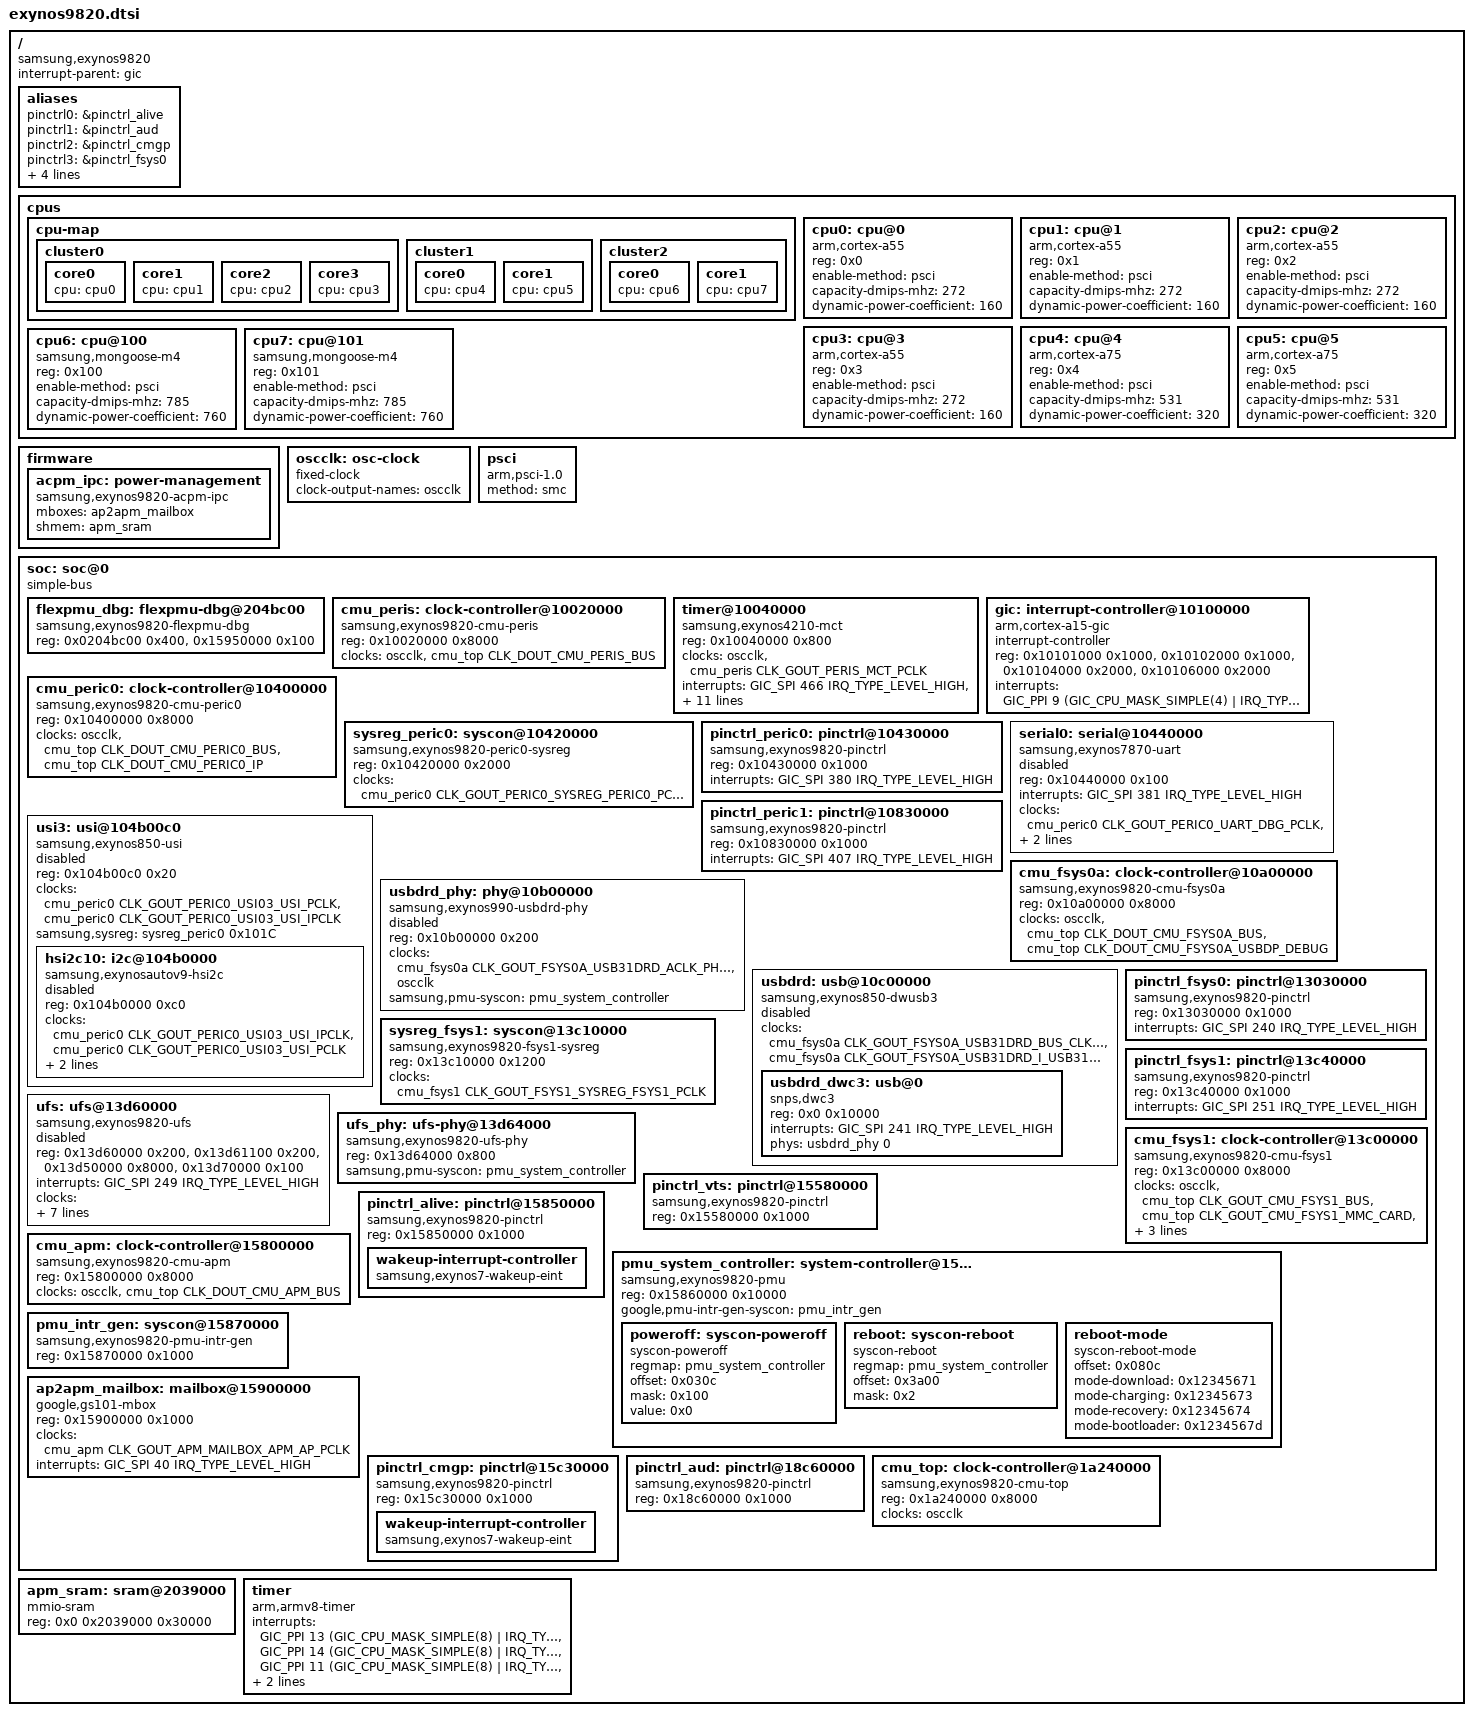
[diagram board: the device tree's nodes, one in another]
// SPDX-License-Identifier: GPL-2.0 OR BSD-3-Clause
/*
 * Samsung Exynos 9820 SoC device tree source
 *
 * Copyright (c) 2025 chiffathefox <chiffathefoxx@gmail.com>
 */

#include <dt-bindings/clock/exynos9820.h>
#include <dt-bindings/interrupt-controller/arm-gic.h>
#include <dt-bindings/interrupt-controller/exynos9820.h>

/ {
	compatible = "samsung,exynos9820";
	#address-cells = <2>;
	#size-cells = <1>;

	interrupt-parent = <&gic>;

	aliases {
		pinctrl0 = &pinctrl_alive;
		pinctrl1 = &pinctrl_aud;
		pinctrl2 = &pinctrl_cmgp;
		pinctrl3 = &pinctrl_fsys0;
		pinctrl4 = &pinctrl_fsys1;
		pinctrl5 = &pinctrl_peric0;
		pinctrl6 = &pinctrl_peric1;
		pinctrl7 = &pinctrl_vts;
	};

	cpus {
		#address-cells = <1>;
		#size-cells = <0>;

		cpu-map {
			cluster0 {
				core0 {
					cpu = <&cpu0>;
				};
				core1 {
					cpu = <&cpu1>;
				};
				core2 {
					cpu = <&cpu2>;
				};
				core3 {
					cpu = <&cpu3>;
				};
			};

			cluster1 {
				core0 {
					cpu = <&cpu4>;
				};
				core1 {
					cpu = <&cpu5>;
				};
			};

			cluster2 {
				core0 {
					cpu = <&cpu6>;
				};
				core1 {
					cpu = <&cpu7>;
				};
			};
		};

		cpu0: cpu@0 {
			device_type = "cpu";
			compatible = "arm,cortex-a55";
			reg = <0x0>;
			enable-method = "psci";
			capacity-dmips-mhz = <272>;
			dynamic-power-coefficient = <160>;
		};

		cpu1: cpu@1 {
			device_type = "cpu";
			compatible = "arm,cortex-a55";
			reg = <0x1>;
			enable-method = "psci";
			capacity-dmips-mhz = <272>;
			dynamic-power-coefficient = <160>;
		};

		cpu2: cpu@2 {
			device_type = "cpu";
			compatible = "arm,cortex-a55";
			reg = <0x2>;
			enable-method = "psci";
			capacity-dmips-mhz = <272>;
			dynamic-power-coefficient = <160>;
		};

		cpu3: cpu@3 {
			device_type = "cpu";
			compatible = "arm,cortex-a55";
			reg = <0x3>;
			enable-method = "psci";
			capacity-dmips-mhz = <272>;
			dynamic-power-coefficient = <160>;
		};

		cpu4: cpu@4 {
			device_type = "cpu";
			compatible = "arm,cortex-a75";
			reg = <0x4>;
			enable-method = "psci";
			capacity-dmips-mhz = <531>;
			dynamic-power-coefficient = <320>;
		};

		cpu5: cpu@5 {
			device_type = "cpu";
			compatible = "arm,cortex-a75";
			reg = <0x5>;
			enable-method = "psci";
			capacity-dmips-mhz = <531>;
			dynamic-power-coefficient = <320>;
		};

		cpu6: cpu@100 {
			device_type = "cpu";
			compatible = "samsung,mongoose-m4";
			reg = <0x100>;
			enable-method = "psci";
			capacity-dmips-mhz = <785>;
			dynamic-power-coefficient = <760>;
		};

		cpu7: cpu@101 {
			device_type = "cpu";
			compatible = "samsung,mongoose-m4";
			reg = <0x101>;
			enable-method = "psci";
			capacity-dmips-mhz = <785>;
			dynamic-power-coefficient = <760>;
		};
	};

	firmware {
		acpm_ipc: power-management {
			compatible = "samsung,exynos9820-acpm-ipc";
			#clock-cells = <1>;
			mboxes = <&ap2apm_mailbox>;
			shmem = <&apm_sram>;
		};
	};

	oscclk: osc-clock {
		compatible = "fixed-clock";
		#clock-cells = <0>;
		clock-output-names = "oscclk";
	};

	/* TODO: A55 PMU */
	/* TODO: A75 PMU */
	/* TODO: Mongoose M4 PMU */

	psci {
		compatible = "arm,psci-1.0";
		method = "smc";
	};

	soc: soc@0 {
		compatible = "simple-bus";
		#address-cells = <1>;
		#size-cells = <1>;
		ranges = <0x0 0x0 0x0 0x20000000>;

		flexpmu_dbg: flexpmu-dbg@204bc00 {
			compatible = "samsung,exynos9820-flexpmu-dbg";
			reg = <0x0204bc00 0x400>,
			      <0x15950000 0x100>;
			reg-names = "data", "rtc";
		};

#if 0
		chipid@10000000 {
			compatible = "samsung,exynos9810-chipid",
				     "samsung,exynos850-chipid";
			reg = <0x10000000 0x100>;
		};
#endif
		cmu_peris: clock-controller@10020000 {
			compatible = "samsung,exynos9820-cmu-peris";
			reg = <0x10020000 0x8000>;
			#clock-cells = <1>;

			clock-names = "oscclk",
				      "bus";
			clocks = <&oscclk>,
				 <&cmu_top CLK_DOUT_CMU_PERIS_BUS>;
		};

		timer@10040000 {
			compatible = "samsung,exynos4210-mct";
			reg = <0x10040000 0x800>;
			clocks = <&oscclk>,
				 <&cmu_peris CLK_GOUT_PERIS_MCT_PCLK>;
			clock-names = "fin_pll",
				      "mct";
			interrupts = <GIC_SPI 466 IRQ_TYPE_LEVEL_HIGH>,
				     <GIC_SPI 467 IRQ_TYPE_LEVEL_HIGH>,
				     <GIC_SPI 468 IRQ_TYPE_LEVEL_HIGH>,
				     <GIC_SPI 469 IRQ_TYPE_LEVEL_HIGH>,
				     <GIC_SPI 470 IRQ_TYPE_LEVEL_HIGH>,
				     <GIC_SPI 471 IRQ_TYPE_LEVEL_HIGH>,
				     <GIC_SPI 472 IRQ_TYPE_LEVEL_HIGH>,
				     <GIC_SPI 473 IRQ_TYPE_LEVEL_HIGH>,
				     <GIC_SPI 474 IRQ_TYPE_LEVEL_HIGH>,
				     <GIC_SPI 475 IRQ_TYPE_LEVEL_HIGH>,
				     <GIC_SPI 476 IRQ_TYPE_LEVEL_HIGH>,
				     <GIC_SPI 477 IRQ_TYPE_LEVEL_HIGH>;
		};

		gic: interrupt-controller@10100000 {
			compatible = "arm,cortex-a15-gic", "arm,cortex-a9-gic";

			#interrupt-cells = <3>;
			#address-cells = <0>;

			interrupt-controller;
			reg = <0x10101000 0x1000>,
			      <0x10102000 0x1000>,
			      <0x10104000 0x2000>,
			      <0x10106000 0x2000>;
			interrupts = <GIC_PPI 9 (GIC_CPU_MASK_SIMPLE(4) |
						 IRQ_TYPE_LEVEL_HIGH)>;
		};

		cmu_peric0: clock-controller@10400000 {
			compatible = "samsung,exynos9820-cmu-peric0";
			reg = <0x10400000 0x8000>;
			#clock-cells = <1>;

			clock-names = "oscclk",
				      "bus",
				      "ip";
			clocks = <&oscclk>,
				 <&cmu_top CLK_DOUT_CMU_PERIC0_BUS>,
				 <&cmu_top CLK_DOUT_CMU_PERIC0_IP>;
		};

		sysreg_peric0: syscon@10420000 {
			compatible = "samsung,exynos9820-peric0-sysreg", "syscon";
			reg = <0x10420000 0x2000>;
			clocks = <&cmu_peric0 CLK_GOUT_PERIC0_SYSREG_PERIC0_PCLK>;
		};

		pinctrl_peric0: pinctrl@10430000 {
			compatible = "samsung,exynos9820-pinctrl";
			reg = <0x10430000 0x1000>;
			interrupts = <GIC_SPI 380 IRQ_TYPE_LEVEL_HIGH>;
		};

		serial0: serial@10440000 {
			compatible = "samsung,exynos7870-uart",
				     "samsung,exynos8895-uart";
			reg = <0x10440000 0x100>;
			interrupts = <GIC_SPI 381 IRQ_TYPE_LEVEL_HIGH>;

#if 0
			pinctrl-names = "default";
			pinctrl-0 = <&uart0_bus>;
#endif

			clock-names = "uart",
				      "clk_uart_baud0";
			clocks = <&cmu_peric0 CLK_GOUT_PERIC0_UART_DBG_PCLK>,
				 <&cmu_peric0 CLK_GOUT_PERIC0_UART_DBG_IPCLK>;

			samsung,uart-fifosize = <256>;

			status = "disabled";
		};

		usi3: usi@104b00c0 {
			compatible = "samsung,exynos850-usi";
			reg = <0x104b00c0 0x20>;
			ranges;

			clock-names = "pclk",
				      "ipclk";
			clocks = <&cmu_peric0 CLK_GOUT_PERIC0_USI03_USI_PCLK>,
				 <&cmu_peric0 CLK_GOUT_PERIC0_USI03_USI_IPCLK>;

			#address-cells = <1>;
			#size-cells = <1>;

			samsung,sysreg = <&sysreg_peric0 0x101C>;
			status = "disabled";

			hsi2c10: i2c@104b0000 {
				compatible = "samsung,exynosautov9-hsi2c";
				reg = <0x104b0000 0xc0>;

				clock-names = "hsi2c",
					      "hsi2c_pclk";
				clocks = <&cmu_peric0 CLK_GOUT_PERIC0_USI03_USI_IPCLK>,
					 <&cmu_peric0 CLK_GOUT_PERIC0_USI03_USI_PCLK>;

				interrupts = <GIC_SPI 388 IRQ_TYPE_LEVEL_HIGH>;
				pinctrl-0 = <&hsi2c10_bus>;
				pinctrl-names = "default";

				#address-cells = <1>;
				#size-cells = <0>;

				status = "disabled";
			};
		};

		pinctrl_peric1: pinctrl@10830000 {
			compatible = "samsung,exynos9820-pinctrl";
			reg = <0x10830000 0x1000>;
			interrupts = <GIC_SPI 407 IRQ_TYPE_LEVEL_HIGH>;
		};

		cmu_fsys0a: clock-controller@10a00000 {
			compatible = "samsung,exynos9820-cmu-fsys0a";
			reg = <0x10a00000 0x8000>;
			#clock-cells = <1>;

			clock-names = "oscclk",
				      "usb31drd",
				      "usbdp_debug";
			clocks = <&oscclk>,
				 <&cmu_top CLK_DOUT_CMU_FSYS0A_BUS>,
				 <&cmu_top CLK_DOUT_CMU_FSYS0A_USBDP_DEBUG>;
		};

		usbdrd_phy: phy@10b00000 {
			compatible = "samsung,exynos990-usbdrd-phy";
			reg = <0x10b00000 0x200>;
			#phy-cells = <1>;

			clock-names = "phy",
				      "ref";
			clocks = <&cmu_fsys0a CLK_GOUT_FSYS0A_USB31DRD_ACLK_PHYCTRL>,
				 <&oscclk>;

			samsung,pmu-syscon = <&pmu_system_controller>;

			status = "disabled";
		};

		usbdrd: usb@10c00000 {
			compatible = "samsung,exynos850-dwusb3";
			ranges = <0x0 0x10c00000 0x10000>;

			clock-names = "bus_early",
				      "ref";
			clocks = <&cmu_fsys0a CLK_GOUT_FSYS0A_USB31DRD_BUS_CLK_EARLY>,
				 <&cmu_fsys0a CLK_GOUT_FSYS0A_USB31DRD_I_USB31DRD_REF_CLK_40>;

			#address-cells = <1>;
			#size-cells = <1>;

			status = "disabled";

			usbdrd_dwc3: usb@0 {
				compatible = "snps,dwc3";
				reg = <0x0 0x10000>;
				interrupts = <GIC_SPI 241 IRQ_TYPE_LEVEL_HIGH>;
				phys = <&usbdrd_phy 0>;
				phy-names = "usb2-phy";
			};
		};

		pinctrl_fsys0: pinctrl@13030000 {
			compatible = "samsung,exynos9820-pinctrl";
			reg = <0x13030000 0x1000>;
			interrupts = <GIC_SPI 240 IRQ_TYPE_LEVEL_HIGH>;
		};

		sysreg_fsys1: syscon@13c10000 {
			compatible = "samsung,exynos9820-fsys1-sysreg", "syscon";
			reg = <0x13c10000 0x1200>;
			clocks = <&cmu_fsys1 CLK_GOUT_FSYS1_SYSREG_FSYS1_PCLK>;
		};

		pinctrl_fsys1: pinctrl@13c40000 {
			compatible = "samsung,exynos9820-pinctrl";
			reg = <0x13c40000 0x1000>;
			interrupts = <GIC_SPI 251 IRQ_TYPE_LEVEL_HIGH>;
		};

		ufs: ufs@13d60000 {
			compatible = "samsung,exynos9820-ufs";
			reg = <0x13d60000 0x200>,	/* 0: HCI standard */
			      <0x13d61100 0x200>,	/* 1: Vendor specificed */
			      <0x13d50000 0x8000>,	/* 2: UNIPRO */
			      <0x13d70000 0x100>;	/* 3: UFS protector */
			reg-names = "hci", "vs_hci", "unipro", "ufsp";

			interrupts = <GIC_SPI 249 IRQ_TYPE_LEVEL_HIGH>;
			clock-names = "core_clk",
				      "sclk_unipro_main",
				      "fmp";
			clocks = <&cmu_fsys1 CLK_GOUT_FSYS1_UFS_EMBD_I_ACLK>,
				 <&cmu_fsys1 CLK_GOUT_FSYS1_UFS_EMBD_I_CLK_UNIPRO>,
				 <&cmu_fsys1 CLK_GOUT_FSYS1_UFS_EMBD_I_FMP_CLK>;
			freq-table-hz = <0 0>,
					<0 0>,
					<0 0>;

#if 0
			pinctrl-names = "default";
			pinctrl-0 = <&ufs_rst_n &ufs_refclk_out>;
#endif

			phys = <&ufs_phy>;
			phy-names = "ufs-phy";

			dma-coherent;
			samsung,sysreg = <&sysreg_fsys1 0x700>;

			status = "disabled";
		};

		ufs_phy: ufs-phy@13d64000 {
			compatible = "samsung,exynos9820-ufs-phy";
			reg = <0x13d64000 0x800>;
			reg-names = "phy-pma";
			#phy-cells = <0>;
			samsung,pmu-syscon = <&pmu_system_controller>;
		};

		cmu_fsys1: clock-controller@13c00000 {
			compatible = "samsung,exynos9820-cmu-fsys1";
			reg = <0x13c00000 0x8000>;
			#clock-cells = <1>;

			clock-names = "oscclk",
				      "bus",
				      "mmc_card",
				      "pcie",
				      "ufs_card",
				      "ufs_embd";
			clocks = <&oscclk>,
				 <&cmu_top CLK_GOUT_CMU_FSYS1_BUS>,
				 <&cmu_top CLK_GOUT_CMU_FSYS1_MMC_CARD>,
				 <&cmu_top CLK_GOUT_CMU_FSYS1_PCIE>,
				 <&cmu_top CLK_GOUT_CMU_FSYS1_UFS_CARD>,
				 <&cmu_top CLK_GOUT_CMU_FSYS1_UFS_EMBD>;
		};

		pinctrl_vts: pinctrl@15580000 {
			compatible = "samsung,exynos9820-pinctrl";
			reg = <0x15580000 0x1000>;
		};

		cmu_apm: clock-controller@15800000 {
			compatible = "samsung,exynos9820-cmu-apm";
			reg = <0x15800000 0x8000>;
			#clock-cells = <1>;

			clock-names = "oscclk",
				      "bus";
			clocks = <&oscclk>,
				 <&cmu_top CLK_DOUT_CMU_APM_BUS>;
		};

		pinctrl_alive: pinctrl@15850000 {
			compatible = "samsung,exynos9820-pinctrl";
			reg = <0x15850000 0x1000>;

			wakeup-interrupt-controller {
				compatible = "samsung,exynos7-wakeup-eint";
			};
		};

		pmu_system_controller: system-controller@15860000 {
			compatible = "samsung,exynos9820-pmu",
				     "samsung,exynos7-pmu",
				     "syscon";
			reg = <0x15860000 0x10000>;

			google,pmu-intr-gen-syscon = <&pmu_intr_gen>;

			poweroff: syscon-poweroff {
				compatible = "syscon-poweroff";
				regmap = <&pmu_system_controller>;
				offset = <0x030c>; /* PS_HOLD_CONTROL */
				mask = <0x100>;
				value = <0x0>; /* De-assert PS_HOLD_EN */
			};

			reboot: syscon-reboot {
				compatible = "syscon-reboot";
				regmap = <&pmu_system_controller>;
				offset = <0x3a00>; /* SWRESET */
				mask = <0x2>;
			};

			reboot-mode {
				compatible = "syscon-reboot-mode";
				offset = <0x080c>; /* SEC_DEBUG_PANIC_INFORM */

				mode-download = <0x12345671>;
				mode-charging = <0x12345673>;
				mode-recovery = <0x12345674>;
				mode-bootloader = <0x1234567d>;
			};
		};

		pmu_intr_gen: syscon@15870000 {
			compatible = "samsung,exynos9820-pmu-intr-gen", "syscon";
			reg = <0x15870000 0x1000>;
		};

		ap2apm_mailbox: mailbox@15900000 {
			compatible = "google,gs101-mbox";
			reg = <0x15900000 0x1000>;
			clocks = <&cmu_apm CLK_GOUT_APM_MAILBOX_APM_AP_PCLK>;
			clock-names = "pclk";
			interrupts = <GIC_SPI 40 IRQ_TYPE_LEVEL_HIGH>;
			#mbox-cells = <0>;
		};

		pinctrl_cmgp: pinctrl@15c30000 {
			compatible = "samsung,exynos9820-pinctrl";
			reg = <0x15c30000 0x1000>;

			wakeup-interrupt-controller {
				compatible = "samsung,exynos7-wakeup-eint";
			};
		};

		pinctrl_aud: pinctrl@18c60000 {
			compatible = "samsung,exynos9820-pinctrl";
			reg = <0x18c60000 0x1000>;
		};

		cmu_top: clock-controller@1a240000 {
			compatible = "samsung,exynos9820-cmu-top";
			reg = <0x1a240000 0x8000>;
			#clock-cells = <1>;

			clock-names = "oscclk";
			clocks = <&oscclk>;
		};

		/* TODO: interrupts, add driver support */
		/* TODO: pinctrl */
		/* TODO: pmu_system_controller */
		/* TODO: DMA */
	};

	apm_sram: sram@2039000 {
		compatible = "mmio-sram";
		reg = <0x0 0x2039000 0x30000>;
		#address-cells = <1>;
		#size-cells = <1>;
		ranges = <0x0 0x0 0x2039000 0x30000>;
	};

	timer {
		compatible = "arm,armv8-timer";

		/* Hypervisor Virtual Timer interrupt is not wired to GIC */
		interrupts = <GIC_PPI 13 (GIC_CPU_MASK_SIMPLE(8) | IRQ_TYPE_LEVEL_LOW)>,
			    	 <GIC_PPI 14 (GIC_CPU_MASK_SIMPLE(8) | IRQ_TYPE_LEVEL_LOW)>,
			    	 <GIC_PPI 11 (GIC_CPU_MASK_SIMPLE(8) | IRQ_TYPE_LEVEL_LOW)>,
			    	 <GIC_PPI 10 (GIC_CPU_MASK_SIMPLE(8) | IRQ_TYPE_LEVEL_LOW)>;

		/*
		 * Non-updatable, broken stock Samsung bootloader does not
		 * configure CNTFRQ_EL0
		 */
		clock-frequency = <26000000>;
	};
};

#include "exynos9820-pinctrl.dtsi"
